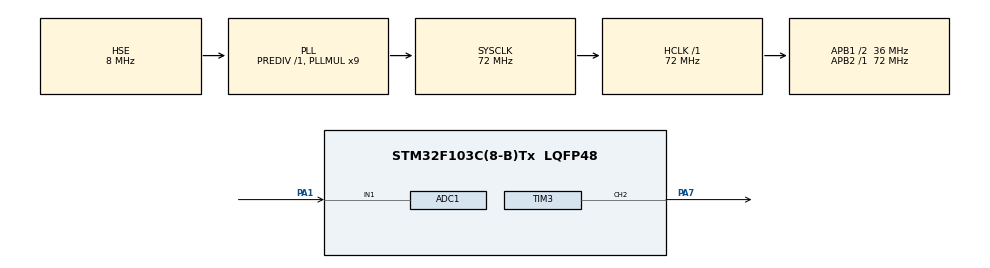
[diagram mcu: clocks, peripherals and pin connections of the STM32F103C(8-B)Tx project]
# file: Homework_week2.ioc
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ADC1.Channel-0\#ChannelRegularConversion=ADC_CHANNEL_1
ADC1.NbrOfConversionFlag=1
ADC1.Rank-0\#ChannelRegularConversion=1
ADC1.SamplingTime-0\#ChannelRegularConversion=ADC_SAMPLETIME_1CYCLE_5
ADC1.master=1
Mcu.Family=STM32F1
Mcu.Name=STM32F103C(8-B)Tx
Mcu.Package=LQFP48
NVIC.PriorityGroup=NVIC_PRIORITYGROUP_4
NVIC.TIM3_IRQn=true\:0\:0\:false\:false\:true\:true\:true\:true
PA1.Signal=ADCx_IN1
PA13.Mode=Serial_Wire
PA13.Signal=SYS_JTMS-SWDIO
PA14.Mode=Serial_Wire
PA14.Signal=SYS_JTCK-SWCLK
PA7.Signal=S_TIM3_CH2
PD0-OSC_IN.Mode=HSE-External-Oscillator
PD0-OSC_IN.Signal=RCC_OSC_IN
PD1-OSC_OUT.Mode=HSE-External-Oscillator
PD1-OSC_OUT.Signal=RCC_OSC_OUT
ProjectManager.HeapSize=0x200
ProjectManager.StackSize=0x400
ProjectManager.TargetToolchain=Makefile
RCC.ADCPresc=RCC_ADCPCLK2_DIV6
RCC.AHBFreq_Value=72000000
RCC.APB1CLKDivider=RCC_HCLK_DIV2
RCC.APB1Freq_Value=36000000
RCC.APB1TimFreq_Value=72000000
RCC.APB2Freq_Value=72000000
RCC.APB2TimFreq_Value=72000000
RCC.HCLKFreq_Value=72000000
RCC.PLLMUL=RCC_PLL_MUL9
RCC.PLLSourceVirtual=RCC_PLLSOURCE_HSE
RCC.SYSCLKFreq_VALUE=72000000
RCC.SYSCLKSource=RCC_SYSCLKSOURCE_PLLCLK
RCC.USBFreq_Value=72000000
SH.ADCx_IN1.0=ADC1_IN1,IN1
SH.S_TIM3_CH2.0=TIM3_CH2,PWM Generation2 CH2
TIM3.AutoReloadPreload=TIM_AUTORELOAD_PRELOAD_ENABLE
TIM3.Channel-PWM\ Generation2\ CH2=TIM_CHANNEL_2
TIM3.Period=20000 - 1
TIM3.Prescaler=72 - 1
board=custom

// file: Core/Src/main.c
/* USER CODE BEGIN Header */
/**
  ******************************************************************************
  * @file           : main.c
  * @brief          : Main program body
  ******************************************************************************
  * @attention
  *
  * Copyright (c) 2026 STMicroelectronics.
  * All rights reserved.
  *
  * This software is licensed under terms that can be found in the LICENSE file
  * in the root directory of this software component.
  * If no LICENSE file comes with this software, it is provided AS-IS.
  *
  ******************************************************************************
  */
/* USER CODE END Header */
#include "main.h"
#include "adc.h"
#include "tim.h"
#include "gpio.h"

void SystemClock_Config(void);

/* USER CODE BEGIN 0 */
int t = 0;//设置为全局变量易于监控
/* USER CODE END 0 */

int main(void)
{

  /* MCU Configuration--------------------------------------------------------*/

  /* Reset of all peripherals, Initializes the Flash interface and the Systick. */
  HAL_Init();

  /* Configure the system clock */
  SystemClock_Config();

  /* Initialize all configured peripherals */
  MX_GPIO_Init();
  MX_ADC1_Init();
  MX_TIM3_Init();
  /* USER CODE BEGIN 2 */
  HAL_TIM_Base_Start(&htim3);
  HAL_TIM_PWM_Start(&htim3,TIM_CHANNEL_2);
  HAL_ADC_Start(&hadc1);
  HAL_ADCEx_Calibration_Start(&hadc1);
  int lastT = 0;//保存上一次t的读数
  int lastTime = HAL_GetTick();
  /* USER CODE END 2 */

  /* Infinite loop */
  while (1)
  {

    /* USER CODE BEGIN 3 */
    HAL_ADC_Start(&hadc1);
    t = (HAL_ADC_GetValue(&hadc1) * 2000 / 4095 + 500) * 10 / 10;
    //不知名同学教我的：用*10/10消掉读数的后一位实现消抖；*2000/4095将得数映射到[0,2000)，之后加上500转换成对[0,500)的映射

     if(HAL_GetTick() - lastTime >= 5 && t - lastT < 100 && lastT - t < 100)
     {
       t = lastT;
       lastTime = HAL_GetTick();
     }
     else
     {
       lastT = t;
       lastTime = HAL_GetTick();
     }
    //消抖：每10ms检测一次，如果ADC输入值的变化量小于10则认为数据变化来源于抖动
    //这一消抖模式理论上有效，但不知为何实验中发现没有显著作用，两种消抖同时启用时，抖动在1-3左右；只启用第一种时，抖动略大但仍然保持在10以内

    if(t > 2500) t = 2500 - 1;
    else if(t < 500) t = 500 - 1;
    //控制t不越界
    __HAL_TIM_SET_COMPARE(&htim3,TIM_CHANNEL_2,t);
    //设置CCR

  }
  /* USER CODE END 3 */
}

void SystemClock_Config(void)
{
  RCC_OscInitTypeDef RCC_OscInitStruct = {0};
  RCC_ClkInitTypeDef RCC_ClkInitStruct = {0};
  RCC_PeriphCLKInitTypeDef PeriphClkInit = {0};

  /** Initializes the RCC Oscillators according to the specified parameters
  * in the RCC_OscInitTypeDef structure.
  */
  RCC_OscInitStruct.OscillatorType = RCC_OSCILLATORTYPE_HSE;
  RCC_OscInitStruct.HSEState = RCC_HSE_ON;
  RCC_OscInitStruct.HSEPredivValue = RCC_HSE_PREDIV_DIV1;
  RCC_OscInitStruct.HSIState = RCC_HSI_ON;
  RCC_OscInitStruct.PLL.PLLState = RCC_PLL_ON;
  RCC_OscInitStruct.PLL.PLLSource = RCC_PLLSOURCE_HSE;
  RCC_OscInitStruct.PLL.PLLMUL = RCC_PLL_MUL9;
  if (HAL_RCC_OscConfig(&RCC_OscInitStruct) != HAL_OK)
  {
    Error_Handler();
  }

  /** Initializes the CPU, AHB and APB buses clocks
  */
  RCC_ClkInitStruct.ClockType = RCC_CLOCKTYPE_HCLK|RCC_CLOCKTYPE_SYSCLK
                              |RCC_CLOCKTYPE_PCLK1|RCC_CLOCKTYPE_PCLK2;
  RCC_ClkInitStruct.SYSCLKSource = RCC_SYSCLKSOURCE_PLLCLK;
  RCC_ClkInitStruct.AHBCLKDivider = RCC_SYSCLK_DIV1;
  RCC_ClkInitStruct.APB1CLKDivider = RCC_HCLK_DIV2;
  RCC_ClkInitStruct.APB2CLKDivider = RCC_HCLK_DIV1;

  if (HAL_RCC_ClockConfig(&RCC_ClkInitStruct, FLASH_LATENCY_2) != HAL_OK)
  {
    Error_Handler();
  }
  PeriphClkInit.PeriphClockSelection = RCC_PERIPHCLK_ADC;
  PeriphClkInit.AdcClockSelection = RCC_ADCPCLK2_DIV6;
  if (HAL_RCCEx_PeriphCLKConfig(&PeriphClkInit) != HAL_OK)
  {
    Error_Handler();
  }
}

void Error_Handler(void)
{
  __disable_irq();
  while (1)
  {
  }
}
